# MLDR187 register map
File version: 1.4
CPU: MDR32F02, little endian
Registers are 32-bit, read-write, no defined reset value unless marked. A register's access mark holds for its fields unless they carry their own. Offsets are from the block's base; [hi:lo] are bit positions; {n}, {i} and the like mark numbered series; 'fields as' and 'values as' point back to an identical list.

## BKP — BKP description
Base 0x40060000
0x00 BKP_WPR — WPR description
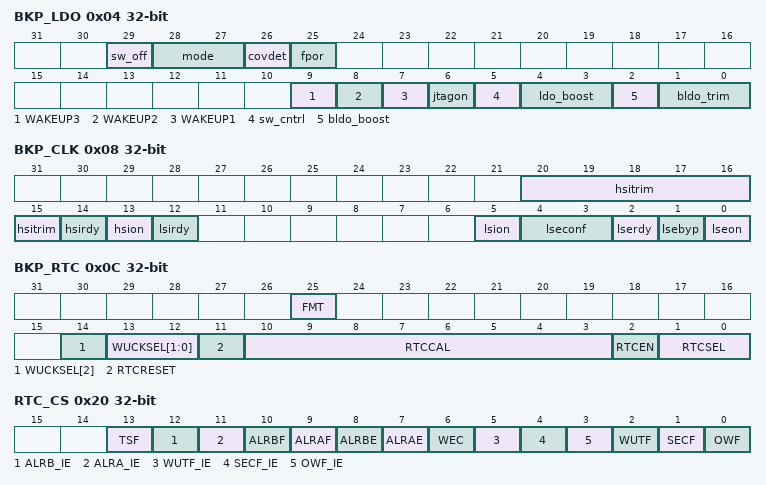
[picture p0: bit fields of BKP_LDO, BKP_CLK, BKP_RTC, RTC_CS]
0x04 BKP_LDO — LDO description
  [29] sw_off — sw_off description
  [28:27] mode — mode description
  [26] covdet — covdet description
  [25] fpor — fpor description
  [9] WAKEUP3 ro — WAKEUP3 description
  [8] WAKEUP2 ro — WAKEUP2 description
  [7] WAKEUP1 ro — WAKEUP1 description
  [6] jtagon — jtagon description
  [5] sw_cntrl — sw_cntrl description
  [4:3] ldo_boost — ldo_boost description
  [2] bldo_boost — bldo_boost description
  [1:0] bldo_trim — bldo_trim description
0x08 BKP_CLK — CLK description
  [20:15] hsitrim — hsitrim description
  [14] hsirdy ro — hsirdy description
  [13] hsion — hsion description
  [12] lsirdy ro — lsirdy description
  [5] lsion — lsion description
  [4:3] lseconf — lseconf description
  [2] lserdy ro — lserdy description
  [1] lsebyp — lsebyp description
  [0] lseon — lseon description
0x0C BKP_RTC — RTC description
  [25] FMT — FMT description
  [14] WUCKSEL[2] — WUCKSEL[2] description
  [13:12] WUCKSEL[1:0] — WUCKSEL[1:0] description
  [11] RTCRESET — RTCRESET description
  [10:3] RTCCAL — RTCCAL description
  [2] RTCEN — RTCEN description
  [1:0] RTCSEL — RTCSEL description
0x10 RTC_WUTR — RTC_WUTR description
0x14 RTC_PREDIV_S — RTC_PREDIV_S description
  [19:0] RTCDIV — RTCDIV description
0x18 RTC_PRL — RTC_PRL description
  [19:0] RTCPRL — RTCPRL description
0x1C RTC_ALRM — RTC_ALRM description
0x20 RTC_CS — RTC_CS description
  [13] TSF — TSF description
  [12] ALRB_IE — ALRB_IE description
  [11] ALRA_IE — ALRA_IE description
  [10] ALRBF — ALRBF description
  [9] ALRAF — ALRAF description
  [8] ALRBE — ALRBE description
  [7] ALRAE — ALRAE description
  [6] WEC ro — WEC description
  [5] WUTF_IE — WUTF_IE description
  [4] SECF_IE — SECF_IE description
  [3] OWF_IE — OWF_IE description
  [2] WUTF — WUTF description
  [1] SECF — SECF description
  [0] OWF — OWF description
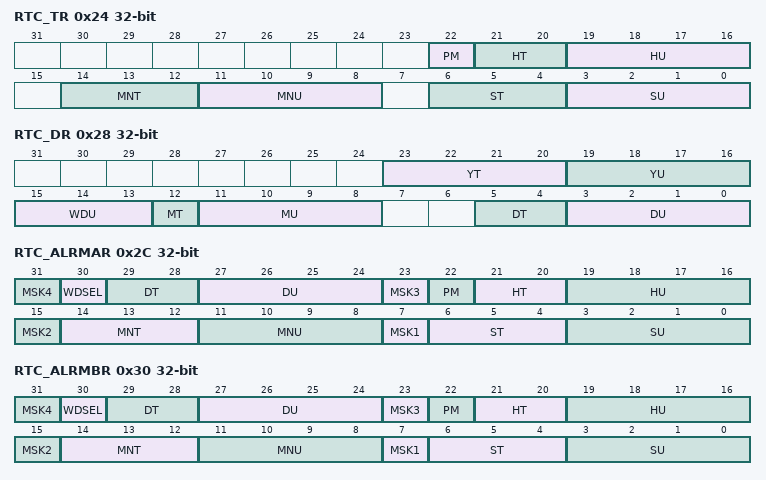
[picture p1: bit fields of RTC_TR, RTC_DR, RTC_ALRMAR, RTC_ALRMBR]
0x24 RTC_TR — RTC_TR description
  [22] PM — PM description
  [21:20] HT — HT description
  [19:16] HU — HU description
  [14:12] MNT — MNT description
  [11:8] MNU — MNU description
  [6:4] ST — ST description
  [3:0] SU — SU description
0x28 RTC_DR — RTC_DR description
  [23:20] YT — YT description
  [19:16] YU — YU description
  [15:13] WDU — WDU description
  [12] MT — MT description
  [11:8] MU — MU description
  [5:4] DT — DT description
  [3:0] DU — DU description
0x2C RTC_ALRMAR — RTC_ALRMAR description
  [8n-1] MSK{n} (n=1..4) — MSK{n} description
  [30] WDSEL — WDSEL description
  [29:28] DT — DT description
  [27:24] DU — DU description
  [22] PM — PM description
  [21:20] HT — HT description
  [19:16] HU — HU description
  [14:12] MNT — MNT description
  [11:8] MNU — MNU description
  [6:4] ST — ST description
  [3:0] SU — SU description
0x30 RTC_ALRMBR — RTC_ALRMBR description
  fields as RTC_ALRMAR
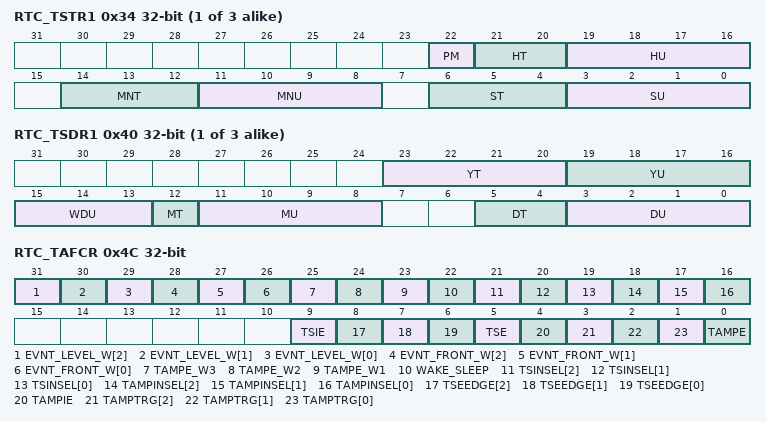
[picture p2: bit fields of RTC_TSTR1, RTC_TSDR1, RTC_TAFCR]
{0x30+4i} RTC_TSTR{i} (i=1..3) — RTC_TSTR{i} description
  fields as RTC_TR
{0x3C+4i} RTC_TSDR{i} (i=1..3) — RTC_TSDR{i} description
  fields as RTC_DR
0x4C RTC_TAFCR — RTC_TAFCR description
  [31] EVNT_LEVEL_W[2] — EVNT_LEVEL_W[2] description. Rev2
  [30] EVNT_LEVEL_W[1] — EVNT_LEVEL_W[1] description. Rev2
  [29] EVNT_LEVEL_W[0] — EVNT_LEVEL_W[0] description. Rev2
  [28] EVNT_FRONT_W[2] — EVNT_FRONT_W[2] description. Rev2
  [27] EVNT_FRONT_W[1] — EVNT_FRONT_W[1] description. Rev2
  [26] EVNT_FRONT_W[0] — EVNT_FRONT_W[0] description. Rev2
  [25] TAMPE_W3 — TAMPE_W3 description. Rev2
  [24] TAMPE_W2 — TAMPE_W2 description. Rev2
  [23] TAMPE_W1 — TAMPE_W1 description. Rev2
  [22] WAKE_SLEEP — WAKE_SLEEP description. Rev2
  [21] TSINSEL[2] — TSINSEL[2] description. Rev2
  [20] TSINSEL[1] — TSINSEL[1] description. Rev2
  [19] TSINSEL[0] — TSINSEL[0] description. Rev2
  [18] TAMPINSEL[2] — TAMPINSEL[2] description. Rev2
  [17] TAMPINSEL[1] — TAMPINSEL[1] description. Rev2
  [16] TAMPINSEL[0] — TAMPINSEL[0] description. Rev2
  [9] TSIE — TSIE description
  [8] TSEEDGE[2] — TSEEDGE[2] description
  [7] TSEEDGE[1] — TSEEDGE[1] description
  [6] TSEEDGE[0] — TSEEDGE[0] description
  [5] TSE — TSE description
  [4] TAMPIE — TAMPIE description
  [3] TAMPTRG[2] — TAMPTRG[2] description
  [2] TAMPTRG[1] — TAMPTRG[1] description
  [1] TAMPTRG[0] — TAMPTRG[0] description
  [0] TAMPE — TAMPE description
